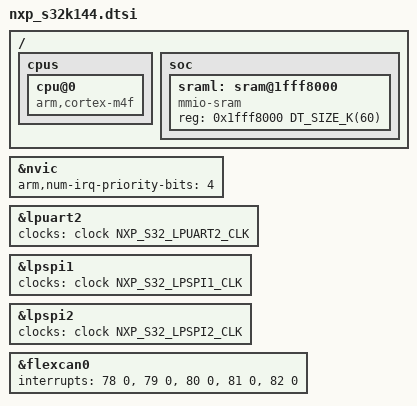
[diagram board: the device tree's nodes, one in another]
/*
 * Copyright 2023 NXP
 *
 * SPDX-License-Identifier: Apache-2.0


	Required target SOC was PS32K144HFT0VLLT
	But wasnt declared in the HAL
	According to datasheet the following were assumed to be compatible

	Compatible  by datasheet -> xS32k144H(F/A)xxLLx
	Hence chose FS32K144HAT0MLLT which closely resembles the required target SOC

 */
// TODO clocks might cause issue change in structure
#include <dt-bindings/clock/nxp_s32k144_clock.h>
#include <nxp/nxp_s32k1xx.dtsi>


/ {
	cpus {
		cpu@0 {
			compatible = "arm,cortex-m4f";
		};
	};

	soc {
		/*
		 * SRAM_L and SRAM_U ranges form a contiguous block but misaligned
		 * and burst accesses cannot occur across the 0x20000000 boundary
		 * that separates the two SRAM arrays. Hence, treat the two arrays
		 * as separate memory ranges.
		 */

		sraml: sram@1fff8000 {
			compatible = "mmio-sram";
			reg = <0x1fff8000 DT_SIZE_K(60)>;
		};

		/* sramu: sram@20000000 {
			compatible = "mmio-sram";
			reg = <0x20000000 DT_SIZE_K(28)>;
		}; */

	};
};

/delete-node/ &lpi2c1;
/delete-node/ &ftm4;
/delete-node/ &ftm5;
/delete-node/ &ftm6;
/delete-node/ &ftm7;

&nvic {
	arm,num-irq-priority-bits = <4>;
};

&lpuart2 {
	clocks = <&clock NXP_S32_LPUART2_CLK>;
};

&lpspi1 {
	clocks = <&clock NXP_S32_LPSPI1_CLK>;
};

&lpspi2 {
	clocks = <&clock NXP_S32_LPSPI2_CLK>;
};

&flexcan0 {
	interrupts = <78 0>, <79 0>, <80 0>, <81 0>, <82 0>;
	interrupt-names = "warning", "error", "wake-up", "mb-0-15", "mb-16-31";
};
